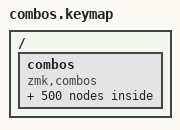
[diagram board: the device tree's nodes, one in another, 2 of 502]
/ {
    combos {
        compatible = "zmk,combos";
        #binding-cells = <2>;

        combo_the {
            key-positions = <12 11 17>;
            bindings      = < &kp T &kp H &kp E >;
        };

        combo_and {
            key-positions = <16 9 22>;
            bindings      = < &kp A &kp N &kp D >;
        };

        combo_in {
            key-positions = <18 9>;
            bindings      = < &kp I &kp N >;
        };

        combo_is {
            key-positions = <18 10>;
            bindings      = < &kp I &kp S >;
        };

        combo_it {
            key-positions = <18 12>;
            bindings      = < &kp I &kp T >;
        };

        combo_you {
            key-positions = <14 7 8>;
            bindings      = < &kp Y &kp O &kp U >;
        };

        combo_that {
            key-positions = <12 11 16>;
            bindings      = < &kp T &kp H &kp A >;
        };

        combo_he {
            key-positions = <11 17>;
            bindings      = < &kp H &kp E >;
        };

        combo_was {
            key-positions = <24 16 10>;
            bindings      = < &kp W &kp A &kp S >;
        };

        combo_for {
            key-positions = <1 7 25>;
            bindings      = < &kp F &kp O &kp R >;
        };

        combo_are {
            key-positions = <16 25 17>;
            bindings      = < &kp A &kp R &kp E >;
        };

        combo_with {
            key-positions = <24 18 12 11>;
            bindings      = < &kp W &kp I &kp T &kp H >;
        };

        combo_as {
            key-positions = <16 10>;
            bindings      = < &kp A &kp S >;
        };

        combo_his {
            key-positions = <11 18 10>;
            bindings      = < &kp H &kp I &kp S >;
        };

        combo_they {
            key-positions = <12 11 17 14>;
            bindings      = < &kp T &kp H &kp E &kp Y >;
        };

        combo_be {
            key-positions = <0 17>;
            bindings      = < &kp B &kp E >;
        };

        combo_at {
            key-positions = <16 12>;
            bindings      = < &kp A &kp T >;
        };

        combo_one {
            key-positions = <7 9 17>;
            bindings      = < &kp O &kp N &kp E >;
        };

        combo_have {
            key-positions = <11 16 20 17>;
            bindings      = < &kp H &kp A &kp V &kp E >;
        };

        combo_this {
            key-positions = <12 11 18 10>;
            bindings      = < &kp T &kp H &kp I &kp S >;
        };

        combo_from {
            key-positions = <1 25 7 13>;
            bindings      = < &kp F &kp R &kp O &kp M >;
        };

        combo_or {
            key-positions = <7 25>;
            bindings      = < &kp O &kp R >;
        };

        combo_had {
            key-positions = <11 16 22>;
            bindings      = < &kp H &kp A &kp D >;
        };

        combo_by {
            key-positions = <0 14>;
            bindings      = < &kp B &kp Y >;
        };

        combo_not {
            key-positions = <9 7 12>;
            bindings      = < &kp N &kp O &kp T >;
        };

        combo_word {
            key-positions = <24 7 25 22>;
            bindings      = < &kp W &kp O &kp R &kp D >;
        };

        combo_but {
            key-positions = <0 8 12>;
            bindings      = < &kp B &kp U &kp T >;
        };

        combo_what {
            key-positions = <24 11 16 12>;
            bindings      = < &kp W &kp H &kp A &kp T >;
        };

        combo_some {
            key-positions = <10 7 13 17>;
            bindings      = < &kp S &kp O &kp M &kp E >;
        };

        combo_we {
            key-positions = <24 17>;
            bindings      = < &kp W &kp E >;
        };

        combo_can {
            key-positions = <15 16 9>;
            bindings      = < &kp C &kp A &kp N >;
        };

        combo_out {
            key-positions = <7 8 12>;
            bindings      = < &kp O &kp U &kp T >;
        };

        combo_were {
            key-positions = <24 17 25>;
            bindings      = < &kp W &kp E &kp R >;
        };

        combo_all {
            key-positions = <16 2>;
            bindings      = < &kp A &kp L >;
        };

        combo_there {
            key-positions = <12 11 17 25>;
            bindings      = < &kp T &kp H &kp E &kp R >;
        };

        combo_when {
            key-positions = <24 11 17 9>;
            bindings      = < &kp W &kp H &kp E &kp N >;
        };

        combo_up {
            key-positions = <8 5>;
            bindings      = < &kp U &kp P >;
        };

        combo_use {
            key-positions = <8 10 17>;
            bindings      = < &kp U &kp S &kp E >;
        };

        combo_your {
            key-positions = <14 7 8 25>;
            bindings      = < &kp Y &kp O &kp U &kp R >;
        };

        combo_how {
            key-positions = <11 7 24>;
            bindings      = < &kp H &kp O &kp W >;
        };

        combo_said {
            key-positions = <10 16 18 22>;
            bindings      = < &kp S &kp A &kp I &kp D >;
        };

        combo_an {
            key-positions = <16 9>;
            bindings      = < &kp A &kp N >;
        };

        combo_each {
            key-positions = <17 16 15 11>;
            bindings      = < &kp E &kp A &kp C &kp H >;
        };

        combo_she {
            key-positions = <10 11 17>;
            bindings      = < &kp S &kp H &kp E >;
        };

        combo_which {
            key-positions = <24 11 18 15>;
            bindings      = < &kp W &kp H &kp I &kp C >;
        };

        combo_do {
            key-positions = <22 7>;
            bindings      = < &kp D &kp O >;
        };

        combo_their {
            key-positions = <12 11 18>;
            bindings      = < &kp T &kp H &kp I >;
        };

        combo_time {
            key-positions = <12 18 13 17>;
            bindings      = < &kp T &kp I &kp M &kp E >;
        };

        combo_if {
            key-positions = <18 1>;
            bindings      = < &kp I &kp F >;
        };

        combo_will {
            key-positions = <24 18 2>;
            bindings      = < &kp W &kp I &kp L >;
        };

        combo_way {
            key-positions = <24 16 14>;
            bindings      = < &kp W &kp A &kp Y >;
        };

        combo_about {
            key-positions = <16 0 7>;
            bindings      = < &kp A &kp B &kp O >;
        };

        combo_many {
            key-positions = <13 16 9 14>;
            bindings      = < &kp M &kp A &kp N &kp Y >;
        };

        combo_then {
            key-positions = <12 11 17 9>;
            bindings      = < &kp T &kp H &kp E &kp N >;
        };

        combo_them {
            key-positions = <12 11 17 13>;
            bindings      = < &kp T &kp H &kp E &kp M >;
        };

        combo_write {
            key-positions = <24 25 18>;
            bindings      = < &kp W &kp R &kp I >;
        };

        combo_would {
            key-positions = <24 7 8>;
            bindings      = < &kp W &kp O &kp U >;
        };

        combo_like {
            key-positions = <2 18 3 17>;
            bindings      = < &kp L &kp I &kp K &kp E >;
        };

        combo_so {
            key-positions = <10 7>;
            bindings      = < &kp S &kp O >;
        };

        combo_these {
            key-positions = <12 11 17 10>;
            bindings      = < &kp T &kp H &kp E &kp S >;
        };

        combo_her {
            key-positions = <11 17 25>;
            bindings      = < &kp H &kp E &kp R >;
        };

        combo_long {
            key-positions = <2 7 9 6>;
            bindings      = < &kp L &kp O &kp N &kp G >;
        };

        combo_make {
            key-positions = <13 16 3 17>;
            bindings      = < &kp M &kp A &kp K &kp E >;
        };

        combo_thing {
            key-positions = <12 11 9>;
            bindings      = < &kp T &kp H &kp N >;
        };

        combo_see {
            key-positions = <10 17>;
            bindings      = < &kp S &kp E >;
        };

        combo_him {
            key-positions = <11 18 13>;
            bindings      = < &kp H &kp I &kp M >;
        };

        combo_two {
            key-positions = <12 24 7>;
            bindings      = < &kp T &kp W &kp O >;
        };

        combo_has {
            key-positions = <11 16 10>;
            bindings      = < &kp H &kp A &kp S >;
        };

        combo_look {
            key-positions = <2 7 3>;
            bindings      = < &kp L &kp O &kp K >;
        };

        combo_more {
            key-positions = <13 7 25 17>;
            bindings      = < &kp M &kp O &kp R &kp E >;
        };

        combo_day {
            key-positions = <22 16 14>;
            bindings      = < &kp D &kp A &kp Y >;
        };

        combo_could {
            key-positions = <15 7 8>;
            bindings      = < &kp C &kp O &kp U >;
        };

        combo_go {
            key-positions = <6 7>;
            bindings      = < &kp G &kp O >;
        };

        combo_come {
            key-positions = <15 7 13 17>;
            bindings      = < &kp C &kp O &kp M &kp E >;
        };

        combo_did {
            key-positions = <22 18>;
            bindings      = < &kp D &kp I >;
        };

        combo_number {
            key-positions = <9 8 0>;
            bindings      = < &kp N &kp U &kp B >;
        };

        combo_sound {
            key-positions = <10 7 9>;
            bindings      = < &kp S &kp O &kp N >;
        };

        combo_most {
            key-positions = <13 7 10 12>;
            bindings      = < &kp M &kp O &kp S &kp T >;
        };

        combo_people {
            key-positions = <5 17 7 2>;
            bindings      = < &kp P &kp E &kp O &kp L >;
        };

        combo_my {
            key-positions = <13 14>;
            bindings      = < &kp M &kp Y >;
        };

        combo_over {
            key-positions = <7 20 17 25>;
            bindings      = < &kp O &kp V &kp E &kp R >;
        };

        combo_know {
            key-positions = <3 9 7 24>;
            bindings      = < &kp K &kp N &kp O &kp W >;
        };

        combo_water {
            key-positions = <24 16 17>;
            bindings      = < &kp W &kp A &kp E >;
        };

        combo_than {
            key-positions = <12 11 16 9>;
            bindings      = < &kp T &kp H &kp A &kp N >;
        };

        combo_call {
            key-positions = <15 16 2>;
            bindings      = < &kp C &kp A &kp L >;
        };

        combo_first {
            key-positions = <1 18 25>;
            bindings      = < &kp F &kp I &kp R >;
        };

        combo_may {
            key-positions = <13 16 14>;
            bindings      = < &kp M &kp A &kp Y >;
        };

        combo_down {
            key-positions = <22 7 24 9>;
            bindings      = < &kp D &kp O &kp W &kp N >;
        };

        combo_side {
            key-positions = <10 18 22 17>;
            bindings      = < &kp S &kp I &kp D &kp E >;
        };

        combo_been {
            key-positions = <0 17 9>;
            bindings      = < &kp B &kp E &kp N >;
        };

        combo_now {
            key-positions = <9 7 24>;
            bindings      = < &kp N &kp O &kp W >;
        };

        combo_find {
            key-positions = <1 18 9 22>;
            bindings      = < &kp F &kp I &kp N &kp D >;
        };

        combo_any {
            key-positions = <16 9 14>;
            bindings      = < &kp A &kp N &kp Y >;
        };

        combo_new {
            key-positions = <9 17 24>;
            bindings      = < &kp N &kp E &kp W >;
        };

        combo_work {
            key-positions = <24 7 25 3>;
            bindings      = < &kp W &kp O &kp R &kp K >;
        };

        combo_part {
            key-positions = <5 16 25 12>;
            bindings      = < &kp P &kp A &kp R &kp T >;
        };

        combo_take {
            key-positions = <12 16 3 17>;
            bindings      = < &kp T &kp A &kp K &kp E >;
        };

        combo_get {
            key-positions = <6 17 12>;
            bindings      = < &kp G &kp E &kp T >;
        };

        combo_place {
            key-positions = <5 2 16>;
            bindings      = < &kp P &kp L &kp A >;
        };

        combo_made {
            key-positions = <13 16 22 17>;
            bindings      = < &kp M &kp A &kp D &kp E >;
        };

        combo_live {
            key-positions = <2 18 20 17>;
            bindings      = < &kp L &kp I &kp V &kp E >;
        };

        combo_where {
            key-positions = <24 11 17 25>;
            bindings      = < &kp W &kp H &kp E &kp R >;
        };

        combo_after {
            key-positions = <16 1 17>;
            bindings      = < &kp A &kp F &kp E >;
        };

        combo_back {
            key-positions = <0 16 15 3>;
            bindings      = < &kp B &kp A &kp C &kp K >;
        };

        combo_little {
            key-positions = <2 18 12 17>;
            bindings      = < &kp L &kp I &kp T &kp E >;
        };

        combo_only {
            key-positions = <7 9 2 14>;
            bindings      = < &kp O &kp N &kp L &kp Y >;
        };

        combo_round {
            key-positions = <25 7 8>;
            bindings      = < &kp R &kp O &kp U >;
        };

        combo_man {
            key-positions = <13 16 9>;
            bindings      = < &kp M &kp A &kp N >;
        };

        combo_year {
            key-positions = <14 17 16 25>;
            bindings      = < &kp Y &kp E &kp A &kp R >;
        };

        combo_came {
            key-positions = <15 16 13 17>;
            bindings      = < &kp C &kp A &kp M &kp E >;
        };

        combo_show {
            key-positions = <10 11 7 24>;
            bindings      = < &kp S &kp H &kp O &kp W >;
        };

        combo_every {
            key-positions = <17 20 25 14>;
            bindings      = < &kp E &kp V &kp R &kp Y >;
        };

        combo_good {
            key-positions = <6 7 22>;
            bindings      = < &kp G &kp O &kp D >;
        };

        combo_me {
            key-positions = <13 17>;
            bindings      = < &kp M &kp E >;
        };

        combo_give {
            key-positions = <6 18 20 17>;
            bindings      = < &kp G &kp I &kp V &kp E >;
        };

        combo_under {
            key-positions = <8 9 22>;
            bindings      = < &kp U &kp N &kp D >;
        };

        combo_name {
            key-positions = <9 16 13 17>;
            bindings      = < &kp N &kp A &kp M &kp E >;
        };

        combo_through {
            key-positions = <12 11 25>;
            bindings      = < &kp T &kp H &kp R >;
        };

        combo_just {
            key-positions = <21 8 10 12>;
            bindings      = < &kp J &kp U &kp S &kp T >;
        };

        combo_sentence {
            key-positions = <10 17 9>;
            bindings      = < &kp S &kp E &kp N >;
        };

        combo_great {
            key-positions = <6 25 17>;
            bindings      = < &kp G &kp R &kp E >;
        };

        combo_think {
            key-positions = <12 11 3>;
            bindings      = < &kp T &kp H &kp K >;
        };

        combo_say {
            key-positions = <10 16 14>;
            bindings      = < &kp S &kp A &kp Y >;
        };

        combo_help {
            key-positions = <11 17 2 5>;
            bindings      = < &kp H &kp E &kp L &kp P >;
        };

        combo_low {
            key-positions = <2 7 24>;
            bindings      = < &kp L &kp O &kp W >;
        };

        combo_line {
            key-positions = <2 18 9 17>;
            bindings      = < &kp L &kp I &kp N &kp E >;
        };

        combo_differ {
            key-positions = <22 1 25>;
            bindings      = < &kp D &kp F &kp R >;
        };

        combo_turn {
            key-positions = <12 8 25 9>;
            bindings      = < &kp T &kp U &kp R &kp N >;
        };

        combo_cause {
            key-positions = <15 16 8>;
            bindings      = < &kp C &kp A &kp U >;
        };

        combo_much {
            key-positions = <13 8 15 11>;
            bindings      = < &kp M &kp U &kp C &kp H >;
        };

        combo_before {
            key-positions = <0 17 1>;
            bindings      = < &kp B &kp E &kp F >;
        };

        combo_move {
            key-positions = <13 7 20 17>;
            bindings      = < &kp M &kp O &kp V &kp E >;
        };

        combo_right {
            key-positions = <25 18 6>;
            bindings      = < &kp R &kp I &kp G >;
        };

        combo_boy {
            key-positions = <0 7 14>;
            bindings      = < &kp B &kp O &kp Y >;
        };

        combo_old {
            key-positions = <7 2 22>;
            bindings      = < &kp O &kp L &kp D >;
        };

        combo_too {
            key-positions = <12 7>;
            bindings      = < &kp T &kp O >;
        };

        combo_same {
            key-positions = <10 16 13 17>;
            bindings      = < &kp S &kp A &kp M &kp E >;
        };

        combo_tell {
            key-positions = <12 17 2>;
            bindings      = < &kp T &kp E &kp L >;
        };

        combo_does {
            key-positions = <22 7 17 10>;
            bindings      = < &kp D &kp O &kp E &kp S >;
        };

        combo_want {
            key-positions = <24 16 9 12>;
            bindings      = < &kp W &kp A &kp N &kp T >;
        };

        combo_air {
            key-positions = <16 18 25>;
            bindings      = < &kp A &kp I &kp R >;
        };

        combo_well {
            key-positions = <24 17 2>;
            bindings      = < &kp W &kp E &kp L >;
        };

        combo_also {
            key-positions = <16 2 10 7>;
            bindings      = < &kp A &kp L &kp S &kp O >;
        };

        combo_play {
            key-positions = <5 2 16 14>;
            bindings      = < &kp P &kp L &kp A &kp Y >;
        };

        combo_small {
            key-positions = <10 13 16 2>;
            bindings      = < &kp S &kp M &kp A &kp L >;
        };

        combo_end {
            key-positions = <17 9 22>;
            bindings      = < &kp E &kp N &kp D >;
        };

        combo_put {
            key-positions = <5 8 12>;
            bindings      = < &kp P &kp U &kp T >;
        };

        combo_home {
            key-positions = <11 7 13 17>;
            bindings      = < &kp H &kp O &kp M &kp E >;
        };

        combo_read {
            key-positions = <25 17 16 22>;
            bindings      = < &kp R &kp E &kp A &kp D >;
        };

        combo_hand {
            key-positions = <11 16 9 22>;
            bindings      = < &kp H &kp A &kp N &kp D >;
        };

        combo_port {
            key-positions = <5 7 25 12>;
            bindings      = < &kp P &kp O &kp R &kp T >;
        };

        combo_large {
            key-positions = <2 16 25>;
            bindings      = < &kp L &kp A &kp R >;
        };

        combo_spell {
            key-positions = <10 5 17 2>;
            bindings      = < &kp S &kp P &kp E &kp L >;
        };

        combo_add {
            key-positions = <16 22>;
            bindings      = < &kp A &kp D >;
        };

        combo_even {
            key-positions = <17 20 9>;
            bindings      = < &kp E &kp V &kp N >;
        };

        combo_land {
            key-positions = <2 16 9 22>;
            bindings      = < &kp L &kp A &kp N &kp D >;
        };

        combo_must {
            key-positions = <13 8 10 12>;
            bindings      = < &kp M &kp U &kp S &kp T >;
        };

        combo_big {
            key-positions = <0 18 6>;
            bindings      = < &kp B &kp I &kp G >;
        };

        combo_high {
            key-positions = <11 18 6>;
            bindings      = < &kp H &kp I &kp G >;
        };

        combo_such {
            key-positions = <10 8 15 11>;
            bindings      = < &kp S &kp U &kp C &kp H >;
        };

        combo_follow {
            key-positions = <1 7 2 24>;
            bindings      = < &kp F &kp O &kp L &kp W >;
        };

        combo_act {
            key-positions = <16 15 12>;
            bindings      = < &kp A &kp C &kp T >;
        };

        combo_why {
            key-positions = <24 11 14>;
            bindings      = < &kp W &kp H &kp Y >;
        };

        combo_ask {
            key-positions = <16 10 3>;
            bindings      = < &kp A &kp S &kp K >;
        };

        combo_men {
            key-positions = <13 17 9>;
            bindings      = < &kp M &kp E &kp N >;
        };

        combo_change {
            key-positions = <15 11 16>;
            bindings      = < &kp C &kp H &kp A >;
        };

        combo_went {
            key-positions = <24 17 9 12>;
            bindings      = < &kp W &kp E &kp N &kp T >;
        };

        combo_light {
            key-positions = <2 18 6>;
            bindings      = < &kp L &kp I &kp G >;
        };

        combo_off {
            key-positions = <7 1>;
            bindings      = < &kp O &kp F >;
        };

        combo_house {
            key-positions = <11 7 8>;
            bindings      = < &kp H &kp O &kp U >;
        };

        combo_picture {
            key-positions = <5 18 15>;
            bindings      = < &kp P &kp I &kp C >;
        };

        combo_try {
            key-positions = <12 25 14>;
            bindings      = < &kp T &kp R &kp Y >;
        };

        combo_us {
            key-positions = <8 10>;
            bindings      = < &kp U &kp S >;
        };

        combo_again {
            key-positions = <16 6 18 9>;
            bindings      = < &kp A &kp G &kp I &kp N >;
        };

        combo_animal {
            key-positions = <16 9 18>;
            bindings      = < &kp A &kp N &kp I >;
        };

        combo_point {
            key-positions = <5 7 18>;
            bindings      = < &kp P &kp O &kp I >;
        };

        combo_mother {
            key-positions = <13 12 11>;
            bindings      = < &kp M &kp T &kp H >;
        };

        combo_world {
            key-positions = <24 7 25>;
            bindings      = < &kp W &kp O &kp R >;
        };

        combo_near {
            key-positions = <9 17 16 25>;
            bindings      = < &kp N &kp E &kp A &kp R >;
        };

        combo_build {
            key-positions = <0 8 18>;
            bindings      = < &kp B &kp U &kp I >;
        };

        combo_self {
            key-positions = <10 17 2 1>;
            bindings      = < &kp S &kp E &kp L &kp F >;
        };

        combo_earth {
            key-positions = <17 16 12>;
            bindings      = < &kp E &kp A &kp T >;
        };

        combo_head {
            key-positions = <11 17 16 22>;
            bindings      = < &kp H &kp E &kp A &kp D >;
        };

        combo_stand {
            key-positions = <10 12 16>;
            bindings      = < &kp S &kp T &kp A >;
        };

        combo_page {
            key-positions = <5 16 6 17>;
            bindings      = < &kp P &kp A &kp G &kp E >;
        };

        combo_should {
            key-positions = <10 11 7>;
            bindings      = < &kp S &kp H &kp O >;
        };

        combo_country {
            key-positions = <15 7 9>;
            bindings      = < &kp C &kp O &kp N >;
        };

        combo_found {
            key-positions = <1 7 8>;
            bindings      = < &kp F &kp O &kp U >;
        };

        combo_answer {
            key-positions = <16 9 10>;
            bindings      = < &kp A &kp N &kp S >;
        };

        combo_school {
            key-positions = <10 15 11>;
            bindings      = < &kp S &kp C &kp H >;
        };

        combo_study {
            key-positions = <10 12 8>;
            bindings      = < &kp S &kp T &kp U >;
        };

        combo_still {
            key-positions = <10 12 18 2>;
            bindings      = < &kp S &kp T &kp I &kp L >;
        };

        combo_learn {
            key-positions = <2 17 16>;
            bindings      = < &kp L &kp E &kp A >;
        };

        combo_plant {
            key-positions = <5 2 9>;
            bindings      = < &kp P &kp L &kp N >;
        };

        combo_cover {
            key-positions = <15 7 20>;
            bindings      = < &kp C &kp O &kp V >;
        };

        combo_food {
            key-positions = <1 7 22>;
            bindings      = < &kp F &kp O &kp D >;
        };

        combo_sun {
            key-positions = <10 8 9>;
            bindings      = < &kp S &kp U &kp N >;
        };

        combo_four {
            key-positions = <1 7 8 25>;
            bindings      = < &kp F &kp O &kp U &kp R >;
        };

        combo_between {
            key-positions = <0 17 12>;
            bindings      = < &kp B &kp E &kp T >;
        };

        combo_state {
            key-positions = <10 12 16 17>;
            bindings      = < &kp S &kp T &kp A &kp E >;
        };

        combo_keep {
            key-positions = <3 17 5>;
            bindings      = < &kp K &kp E &kp P >;
        };

        combo_eye {
            key-positions = <17 14>;
            bindings      = < &kp E &kp Y >;
        };

        combo_never {
            key-positions = <9 17 20 25>;
            bindings      = < &kp N &kp E &kp V &kp R >;
        };

        combo_last {
            key-positions = <2 16 10 12>;
            bindings      = < &kp L &kp A &kp S &kp T >;
        };

        combo_thought {
            key-positions = <12 11 7>;
            bindings      = < &kp T &kp H &kp O >;
        };

        combo_city {
            key-positions = <15 18 12 14>;
            bindings      = < &kp C &kp I &kp T &kp Y >;
        };

        combo_tree {
            key-positions = <12 25 17>;
            bindings      = < &kp T &kp R &kp E >;
        };

        combo_cross {
            key-positions = <15 25 7 10>;
            bindings      = < &kp C &kp R &kp O &kp S >;
        };

        combo_farm {
            key-positions = <1 16 25 13>;
            bindings      = < &kp F &kp A &kp R &kp M >;
        };

        combo_hard {
            key-positions = <11 16 25 22>;
            bindings      = < &kp H &kp A &kp R &kp D >;
        };

        combo_start {
            key-positions = <10 12 16 25>;
            bindings      = < &kp S &kp T &kp A &kp R >;
        };

        combo_might {
            key-positions = <13 18 6>;
            bindings      = < &kp M &kp I &kp G >;
        };

        combo_story {
            key-positions = <10 12 7>;
            bindings      = < &kp S &kp T &kp O >;
        };

        combo_far {
            key-positions = <1 16 25>;
            bindings      = < &kp F &kp A &kp R >;
        };

        combo_sea {
            key-positions = <10 17 16>;
            bindings      = < &kp S &kp E &kp A >;
        };

        combo_draw {
            key-positions = <22 25 16 24>;
            bindings      = < &kp D &kp R &kp A &kp W >;
        };

        combo_left {
            key-positions = <2 17 1 12>;
            bindings      = < &kp L &kp E &kp F &kp T >;
        };

        combo_late {
            key-positions = <2 16 12 17>;
            bindings      = < &kp L &kp A &kp T &kp E >;
        };

        combo_run {
            key-positions = <25 8 9>;
            bindings      = < &kp R &kp U &kp N >;
        };

        combo_while {
            key-positions = <24 11 18>;
            bindings      = < &kp W &kp H &kp I >;
        };

        combo_press {
            key-positions = <5 25 17 10>;
            bindings      = < &kp P &kp R &kp E &kp S >;
        };

        combo_close {
            key-positions = <15 2 7>;
            bindings      = < &kp C &kp L &kp O >;
        };

        combo_night {
            key-positions = <9 18 11>;
            bindings      = < &kp N &kp I &kp H >;
        };

        combo_real {
            key-positions = <25 17 16 2>;
            bindings      = < &kp R &kp E &kp A &kp L >;
        };

        combo_life {
            key-positions = <2 18 1 17>;
            bindings      = < &kp L &kp I &kp F &kp E >;
        };

        combo_few {
            key-positions = <1 17 24>;
            bindings      = < &kp F &kp E &kp W >;
        };

        combo_north {
            key-positions = <9 7 25>;
            bindings      = < &kp N &kp O &kp R >;
        };

        combo_open {
            key-positions = <7 5 17 9>;
            bindings      = < &kp O &kp P &kp E &kp N >;
        };

        combo_seem {
            key-positions = <10 17 13>;
            bindings      = < &kp S &kp E &kp M >;
        };

        combo_together {
            key-positions = <12 6 11>;
            bindings      = < &kp T &kp G &kp H >;
        };

        combo_next {
            key-positions = <9 17 19 12>;
            bindings      = < &kp N &kp E &kp X &kp T >;
        };

        combo_white {
            key-positions = <24 11 12>;
            bindings      = < &kp W &kp H &kp T >;
        };

        combo_children {
            key-positions = <15 11 18>;
            bindings      = < &kp C &kp H &kp I >;
        };

        combo_begin {
            key-positions = <0 17 6>;
            bindings      = < &kp B &kp E &kp G >;
        };

        combo_got {
            key-positions = <6 7 12>;
            bindings      = < &kp G &kp O &kp T >;
        };

        combo_walk {
            key-positions = <24 16 2 3>;
            bindings      = < &kp W &kp A &kp L &kp K >;
        };

        combo_example {
            key-positions = <17 19 16>;
            bindings      = < &kp E &kp X &kp A >;
        };

        combo_group {
            key-positions = <6 25 7>;
            bindings      = < &kp G &kp R &kp O >;
        };

        combo_always {
            key-positions = <16 2 24>;
            bindings      = < &kp A &kp L &kp W >;
        };

        combo_music {
            key-positions = <13 8 10>;
            bindings      = < &kp M &kp U &kp S >;
        };

        combo_those {
            key-positions = <12 11 10>;
            bindings      = < &kp T &kp H &kp S >;
        };

        combo_both {
            key-positions = <0 7 12 11>;
            bindings      = < &kp B &kp O &kp T &kp H >;
        };

        combo_mark {
            key-positions = <13 16 25 3>;
            bindings      = < &kp M &kp A &kp R &kp K >;
        };

        combo_often {
            key-positions = <7 1 12>;
            bindings      = < &kp O &kp F &kp T >;
        };

        combo_letter {
            key-positions = <2 17 12 25>;
            bindings      = < &kp L &kp E &kp T &kp R >;
        };

        combo_until {
            key-positions = <8 9 12>;
            bindings      = < &kp U &kp N &kp T >;
        };

        combo_mile {
            key-positions = <13 18 2 17>;
            bindings      = < &kp M &kp I &kp L &kp E >;
        };

        combo_river {
            key-positions = <25 18 20 17>;
            bindings      = < &kp R &kp I &kp V &kp E >;
        };

        combo_car {
            key-positions = <15 16 25>;
            bindings      = < &kp C &kp A &kp R >;
        };

        combo_feet {
            key-positions = <1 17 12>;
            bindings      = < &kp F &kp E &kp T >;
        };

        combo_care {
            key-positions = <15 16 25 17>;
            bindings      = < &kp C &kp A &kp R &kp E >;
        };

        combo_second {
            key-positions = <10 17 15>;
            bindings      = < &kp S &kp E &kp C >;
        };

        combo_book {
            key-positions = <0 7 3>;
            bindings      = < &kp B &kp O &kp K >;
        };

        combo_carry {
            key-positions = <15 16 25 14>;
            bindings      = < &kp C &kp A &kp R &kp Y >;
        };

        combo_took {
            key-positions = <12 7 3>;
            bindings      = < &kp T &kp O &kp K >;
        };

        combo_science {
            key-positions = <10 15 18>;
            bindings      = < &kp S &kp C &kp I >;
        };

        combo_room {
            key-positions = <25 7 13>;
            bindings      = < &kp R &kp O &kp M >;
        };

        combo_friend {
            key-positions = <1 25 17>;
            bindings      = < &kp F &kp R &kp E >;
        };

        combo_began {
            key-positions = <0 17 16>;
            bindings      = < &kp B &kp E &kp A >;
        };

        combo_idea {
            key-positions = <18 22 17 16>;
            bindings      = < &kp I &kp D &kp E &kp A >;
        };

        combo_fish {
            key-positions = <1 18 10 11>;
            bindings      = < &kp F &kp I &kp S &kp H >;
        };

        combo_mountain {
            key-positions = <13 7 8>;
            bindings      = < &kp M &kp O &kp U >;
        };

        combo_stop {
            key-positions = <10 12 7 5>;
            bindings      = < &kp S &kp T &kp O &kp P >;
        };

        combo_once {
            key-positions = <7 9 15 17>;
            bindings      = < &kp O &kp N &kp C &kp E >;
        };

        combo_base {
            key-positions = <0 16 10 17>;
            bindings      = < &kp B &kp A &kp S &kp E >;
        };

        combo_hear {
            key-positions = <11 17 16 25>;
            bindings      = < &kp H &kp E &kp A &kp R >;
        };

        combo_horse {
            key-positions = <11 7 25>;
            bindings      = < &kp H &kp O &kp R >;
        };

        combo_cut {
            key-positions = <15 8 12>;
            bindings      = < &kp C &kp U &kp T >;
        };

        combo_sure {
            key-positions = <10 8 25 17>;
            bindings      = < &kp S &kp U &kp R &kp E >;
        };

        combo_watch {
            key-positions = <24 16 12>;
            bindings      = < &kp W &kp A &kp T >;
        };

        combo_color {
            key-positions = <15 7 2 25>;
            bindings      = < &kp C &kp O &kp L &kp R >;
        };

        combo_face {
            key-positions = <1 16 15 17>;
            bindings      = < &kp F &kp A &kp C &kp E >;
        };

        combo_wood {
            key-positions = <24 7 22>;
            bindings      = < &kp W &kp O &kp D >;
        };

        combo_main {
            key-positions = <13 16 18 9>;
            bindings      = < &kp M &kp A &kp I &kp N >;
        };

        combo_enough {
            key-positions = <17 9 8>;
            bindings      = < &kp E &kp N &kp U >;
        };

        combo_plain {
            key-positions = <5 2 18>;
            bindings      = < &kp P &kp L &kp I >;
        };

        combo_girl {
            key-positions = <6 18 25 2>;
            bindings      = < &kp G &kp I &kp R &kp L >;
        };

        combo_usual {
            key-positions = <8 10 16 2>;
            bindings      = < &kp U &kp S &kp A &kp L >;
        };

        combo_young {
            key-positions = <14 7 9>;
            bindings      = < &kp Y &kp O &kp N >;
        };

        combo_ready {
            key-positions = <25 17 14>;
            bindings      = < &kp R &kp E &kp Y >;
        };

        combo_above {
            key-positions = <16 0 20>;
            bindings      = < &kp A &kp B &kp V >;
        };

        combo_ever {
            key-positions = <17 20 25>;
            bindings      = < &kp E &kp V &kp R >;
        };

        combo_red {
            key-positions = <25 17 22>;
            bindings      = < &kp R &kp E &kp D >;
        };

        combo_though {
            key-positions = <12 11 8>;
            bindings      = < &kp T &kp H &kp U >;
        };

        combo_feel {
            key-positions = <1 17 2>;
            bindings      = < &kp F &kp E &kp L >;
        };

        combo_talk {
            key-positions = <12 16 2 3>;
            bindings      = < &kp T &kp A &kp L &kp K >;
        };

        combo_bird {
            key-positions = <0 18 25 22>;
            bindings      = < &kp B &kp I &kp R &kp D >;
        };

        combo_body {
            key-positions = <0 7 22 14>;
            bindings      = < &kp B &kp O &kp D &kp Y >;
        };

        combo_family {
            key-positions = <1 16 13>;
            bindings      = < &kp F &kp A &kp M >;
        };

        combo_direct {
            key-positions = <22 18 25>;
            bindings      = < &kp D &kp I &kp R >;
        };

        combo_pose {
            key-positions = <5 7 10 17>;
            bindings      = < &kp P &kp O &kp S &kp E >;
        };

        combo_leave {
            key-positions = <2 17 16 20>;
            bindings      = < &kp L &kp E &kp A &kp V >;
        };

        combo_song {
            key-positions = <10 7 9 6>;
            bindings      = < &kp S &kp O &kp N &kp G >;
        };

        combo_measure {
            key-positions = <13 17 16>;
            bindings      = < &kp M &kp E &kp A >;
        };

        combo_door {
            key-positions = <22 7 25>;
            bindings      = < &kp D &kp O &kp R >;
        };

        combo_product {
            key-positions = <5 25 7>;
            bindings      = < &kp P &kp R &kp O >;
        };

        combo_black {
            key-positions = <0 2 16>;
            bindings      = < &kp B &kp L &kp A >;
        };

        combo_short {
            key-positions = <10 11 25>;
            bindings      = < &kp S &kp H &kp R >;
        };

        combo_numeral {
            key-positions = <9 8 13>;
            bindings      = < &kp N &kp U &kp M >;
        };

        combo_class {
            key-positions = <15 2 16 10>;
            bindings      = < &kp C &kp L &kp A &kp S >;
        };

        combo_wind {
            key-positions = <24 18 9 22>;
            bindings      = < &kp W &kp I &kp N &kp D >;
        };

        combo_question {
            key-positions = <4 8 9>;
            bindings      = < &kp Q &kp U &kp N >;
        };

        combo_happen {
            key-positions = <11 16 5>;
            bindings      = < &kp H &kp A &kp P >;
        };

        combo_complete {
            key-positions = <15 7 13>;
            bindings      = < &kp C &kp O &kp M >;
        };

        combo_ship {
            key-positions = <10 11 18 5>;
            bindings      = < &kp S &kp H &kp I &kp P >;
        };

        combo_half {
            key-positions = <11 16 2 1>;
            bindings      = < &kp H &kp A &kp L &kp F >;
        };

        combo_rock {
            key-positions = <25 7 15 3>;
            bindings      = < &kp R &kp O &kp C &kp K >;
        };

        combo_order {
            key-positions = <7 25 22 17>;
            bindings      = < &kp O &kp R &kp D &kp E >;
        };

        combo_fire {
            key-positions = <1 18 25 17>;
            bindings      = < &kp F &kp I &kp R &kp E >;
        };

        combo_south {
            key-positions = <10 8 11>;
            bindings      = < &kp S &kp U &kp H >;
        };

        combo_problem {
            key-positions = <5 25 0>;
            bindings      = < &kp P &kp R &kp B >;
        };

        combo_piece {
            key-positions = <5 18 17 15>;
            bindings      = < &kp P &kp I &kp E &kp C >;
        };

        combo_told {
            key-positions = <12 7 2 22>;
            bindings      = < &kp T &kp O &kp L &kp D >;
        };

        combo_knew {
            key-positions = <3 9 17 24>;
            bindings      = < &kp K &kp N &kp E &kp W >;
        };

        combo_pass {
            key-positions = <5 16 10>;
            bindings      = < &kp P &kp A &kp S >;
        };

        combo_since {
            key-positions = <10 18 9>;
            bindings      = < &kp S &kp I &kp N >;
        };

        combo_top {
            key-positions = <12 7 5>;
            bindings      = < &kp T &kp O &kp P >;
        };

        combo_whole {
            key-positions = <24 11 2>;
            bindings      = < &kp W &kp H &kp L >;
        };

        combo_king {
            key-positions = <3 18 9 6>;
            bindings      = < &kp K &kp I &kp N &kp G >;
        };

        combo_space {
            key-positions = <10 5 15>;
            bindings      = < &kp S &kp P &kp C >;
        };

        combo_heard {
            key-positions = <11 17 16>;
            bindings      = < &kp H &kp E &kp A >;
        };

        combo_best {
            key-positions = <0 17 10 12>;
            bindings      = < &kp B &kp E &kp S &kp T >;
        };

        combo_hour {
            key-positions = <11 7 8 25>;
            bindings      = < &kp H &kp O &kp U &kp R >;
        };

        combo_better {
            key-positions = <0 17 12 25>;
            bindings      = < &kp B &kp E &kp T &kp R >;
        };

        combo_true {
            key-positions = <12 25 8 17>;
            bindings      = < &kp T &kp R &kp U &kp E >;
        };

        combo_during {
            key-positions = <22 8 25>;
            bindings      = < &kp D &kp U &kp R >;
        };

        combo_hundred {
            key-positions = <11 8 9>;
            bindings      = < &kp H &kp U &kp N >;
        };

        combo_remember {
            key-positions = <25 17 13 0>;
            bindings      = < &kp R &kp E &kp M &kp B >;
        };

        combo_step {
            key-positions = <10 12 17 5>;
            bindings      = < &kp S &kp T &kp E &kp P >;
        };

        combo_early {
            key-positions = <17 16 14>;
            bindings      = < &kp E &kp A &kp Y >;
        };

        combo_hold {
            key-positions = <11 7 2 22>;
            bindings      = < &kp H &kp O &kp L &kp D >;
        };

        combo_west {
            key-positions = <24 17 10 12>;
            bindings      = < &kp W &kp E &kp S &kp T >;
        };

        combo_ground {
            key-positions = <6 25 8>;
            bindings      = < &kp G &kp R &kp U >;
        };

        combo_interest {
            key-positions = <18 9 25>;
            bindings      = < &kp I &kp N &kp R >;
        };

        combo_fast {
            key-positions = <1 16 10 12>;
            bindings      = < &kp F &kp A &kp S &kp T >;
        };

        combo_verb {
            key-positions = <20 17 25 0>;
            bindings      = < &kp V &kp E &kp R &kp B >;
        };

        combo_sing {
            key-positions = <10 18 9 6>;
            bindings      = < &kp S &kp I &kp N &kp G >;
        };

        combo_listen {
            key-positions = <2 18 10>;
            bindings      = < &kp L &kp I &kp S >;
        };

        combo_six {
            key-positions = <10 18 19>;
            bindings      = < &kp S &kp I &kp X >;
        };

        combo_table {
            key-positions = <12 16 0>;
            bindings      = < &kp T &kp A &kp B >;
        };

        combo_travel {
            key-positions = <12 25 16>;
            bindings      = < &kp T &kp R &kp A >;
        };

        combo_less {
            key-positions = <2 17 10 10>;
            bindings      = < &kp L &kp E &kp S &kp S >;
        };

        combo_morning {
            key-positions = <13 7 18>;
            bindings      = < &kp M &kp O &kp I >;
        };

        combo_ten {
            key-positions = <12 17 9>;
            bindings      = < &kp T &kp E &kp N >;
        };

        combo_simple {
            key-positions = <10 18 13>;
            bindings      = < &kp S &kp I &kp M >;
        };

        combo_several {
            key-positions = <10 17 20>;
            bindings      = < &kp S &kp E &kp V >;
        };

        combo_vowel {
            key-positions = <20 7 24>;
            bindings      = < &kp V &kp O &kp W >;
        };

        combo_toward {
            key-positions = <12 7 16>;
            bindings      = < &kp T &kp O &kp A >;
        };

        combo_war {
            key-positions = <24 16 25>;
            bindings      = < &kp W &kp A &kp R >;
        };

        combo_lay {
            key-positions = <2 16 14>;
            bindings      = < &kp L &kp A &kp Y >;
        };

        combo_against {
            key-positions = <16 6 18>;
            bindings      = < &kp A &kp G &kp I >;
        };

        combo_pattern {
            key-positions = <5 16 12>;
            bindings      = < &kp P &kp A &kp T >;
        };

        combo_slow {
            key-positions = <10 2 7 24>;
            bindings      = < &kp S &kp L &kp O &kp W >;
        };

        combo_love {
            key-positions = <2 7 20 17>;
            bindings      = < &kp L &kp O &kp V &kp E >;
        };

        combo_person {
            key-positions = <5 17 10>;
            bindings      = < &kp P &kp E &kp S >;
        };

        combo_money {
            key-positions = <13 7 9>;
            bindings      = < &kp M &kp O &kp N >;
        };

        combo_serve {
            key-positions = <10 17 25 20>;
            bindings      = < &kp S &kp E &kp R &kp V >;
        };

        combo_appear {
            key-positions = <16 5 17 25>;
            bindings      = < &kp A &kp P &kp E &kp R >;
        };

        combo_road {
            key-positions = <25 7 16 22>;
            bindings      = < &kp R &kp O &kp A &kp D >;
        };

        combo_map {
            key-positions = <13 16 5>;
            bindings      = < &kp M &kp A &kp P >;
        };

        combo_rain {
            key-positions = <25 16 18 9>;
            bindings      = < &kp R &kp A &kp I &kp N >;
        };

        combo_rule {
            key-positions = <25 8 2 17>;
            bindings      = < &kp R &kp U &kp L &kp E >;
        };

        combo_govern {
            key-positions = <6 7 20>;
            bindings      = < &kp G &kp O &kp V >;
        };

        combo_pull {
            key-positions = <5 8 2>;
            bindings      = < &kp P &kp U &kp L >;
        };

        combo_cold {
            key-positions = <15 7 2 22>;
            bindings      = < &kp C &kp O &kp L &kp D >;
        };

        combo_notice {
            key-positions = <9 12 18>;
            bindings      = < &kp N &kp T &kp I >;
        };

        combo_voice {
            key-positions = <20 7 18>;
            bindings      = < &kp V &kp O &kp I >;
        };

        combo_unit {
            key-positions = <8 9 18 12>;
            bindings      = < &kp U &kp N &kp I &kp T >;
        };

        combo_power {
            key-positions = <5 7 24>;
            bindings      = < &kp P &kp O &kp W >;
        };

        combo_town {
            key-positions = <12 7 24 9>;
            bindings      = < &kp T &kp O &kp W &kp N >;
        };

        combo_fine {
            key-positions = <1 18 9 17>;
            bindings      = < &kp F &kp I &kp N &kp E >;
        };

        combo_certain {
            key-positions = <15 17 25>;
            bindings      = < &kp C &kp E &kp R >;
        };

        combo_fly {
            key-positions = <1 2 14>;
            bindings      = < &kp F &kp L &kp Y >;
        };

        combo_fall {
            key-positions = <1 16 2>;
            bindings      = < &kp F &kp A &kp L >;
        };

        combo_lead {
            key-positions = <2 17 16 22>;
            bindings      = < &kp L &kp E &kp A &kp D >;
        };

        combo_cry {
            key-positions = <15 25 14>;
            bindings      = < &kp C &kp R &kp Y >;
        };

        combo_machine {
            key-positions = <13 16 15>;
            bindings      = < &kp M &kp A &kp C >;
        };

        combo_note {
            key-positions = <9 7 12 17>;
            bindings      = < &kp N &kp O &kp T &kp E >;
        };

        combo_wait {
            key-positions = <24 16 18 12>;
            bindings      = < &kp W &kp A &kp I &kp T >;
        };

        combo_plan {
            key-positions = <5 2 16 9>;
            bindings      = < &kp P &kp L &kp A &kp N >;
        };

        combo_figure {
            key-positions = <1 18 6>;
            bindings      = < &kp F &kp I &kp G >;
        };

        combo_noun {
            key-positions = <9 7 8>;
            bindings      = < &kp N &kp O &kp U >;
        };

        combo_field {
            key-positions = <1 18 17>;
            bindings      = < &kp F &kp I &kp E >;
        };

        combo_rest {
            key-positions = <25 17 10 12>;
            bindings      = < &kp R &kp E &kp S &kp T >;
        };

        combo_correct {
            key-positions = <15 7 25>;
            bindings      = < &kp C &kp O &kp R >;
        };

        combo_able {
            key-positions = <16 0 2 17>;
            bindings      = < &kp A &kp B &kp L &kp E >;
        };

        combo_pound {
            key-positions = <5 7 8>;
            bindings      = < &kp P &kp O &kp U >;
        };

        combo_done {
            key-positions = <22 7 9 17>;
            bindings      = < &kp D &kp O &kp N &kp E >;
        };

        combo_beauty {
            key-positions = <0 17 8>;
            bindings      = < &kp B &kp E &kp U >;
        };

        combo_drive {
            key-positions = <22 25 20>;
            bindings      = < &kp D &kp R &kp V >;
        };

        combo_stood {
            key-positions = <10 12 7 22>;
            bindings      = < &kp S &kp T &kp O &kp D >;
        };

        combo_contain {
            key-positions = <15 7 12>;
            bindings      = < &kp C &kp O &kp T >;
        };

        combo_front {
            key-positions = <1 25 9>;
            bindings      = < &kp F &kp R &kp N >;
        };

        combo_teach {
            key-positions = <12 17 15>;
            bindings      = < &kp T &kp E &kp C >;
        };

        combo_week {
            key-positions = <24 17 3>;
            bindings      = < &kp W &kp E &kp K >;
        };

        combo_final {
            key-positions = <1 18 9>;
            bindings      = < &kp F &kp I &kp N >;
        };

        combo_gave {
            key-positions = <6 16 20 17>;
            bindings      = < &kp G &kp A &kp V &kp E >;
        };

        combo_green {
            key-positions = <6 25 17 9>;
            bindings      = < &kp G &kp R &kp E &kp N >;
        };

        combo_oh {
            key-positions = <7 11>;
            bindings      = < &kp O &kp H >;
        };

        combo_quick {
            key-positions = <4 8 18>;
            bindings      = < &kp Q &kp U &kp I >;
        };

        combo_develop {
            key-positions = <22 17 20>;
            bindings      = < &kp D &kp E &kp V >;
        };

        combo_ocean {
            key-positions = <7 15 17>;
            bindings      = < &kp O &kp C &kp E >;
        };

        combo_warm {
            key-positions = <24 16 25 13>;
            bindings      = < &kp W &kp A &kp R &kp M >;
        };

        combo_minute {
            key-positions = <13 18 9>;
            bindings      = < &kp M &kp I &kp N >;
        };

        combo_strong {
            key-positions = <10 12 25>;
            bindings      = < &kp S &kp T &kp R >;
        };

        combo_special {
            key-positions = <10 5 18>;
            bindings      = < &kp S &kp P &kp I >;
        };

        combo_mind {
            key-positions = <13 18 9 22>;
            bindings      = < &kp M &kp I &kp N &kp D >;
        };

        combo_behind {
            key-positions = <0 17 11>;
            bindings      = < &kp B &kp E &kp H >;
        };

        combo_clear {
            key-positions = <15 2 17>;
            bindings      = < &kp C &kp L &kp E >;
        };

        combo_tail {
            key-positions = <12 16 18 2>;
            bindings      = < &kp T &kp A &kp I &kp L >;
        };

        combo_produce {
            key-positions = <5 25 22>;
            bindings      = < &kp P &kp R &kp D >;
        };

        combo_fact {
            key-positions = <1 16 15 12>;
            bindings      = < &kp F &kp A &kp C &kp T >;
        };

        combo_inch {
            key-positions = <18 9 15 11>;
            bindings      = < &kp I &kp N &kp C &kp H >;
        };

        combo_multiply {
            key-positions = <13 8 2>;
            bindings      = < &kp M &kp U &kp L >;
        };

        combo_nothing {
            key-positions = <9 7 11>;
            bindings      = < &kp N &kp O &kp H >;
        };

        combo_course {
            key-positions = <15 7 10>;
            bindings      = < &kp C &kp O &kp S >;
        };

        combo_stay {
            key-positions = <10 12 16 14>;
            bindings      = < &kp S &kp T &kp A &kp Y >;
        };

        combo_wheel {
            key-positions = <24 11 17 2>;
            bindings      = < &kp W &kp H &kp E &kp L >;
        };

        combo_full {
            key-positions = <1 8 2>;
            bindings      = < &kp F &kp U &kp L >;
        };

        combo_force {
            key-positions = <1 7 15>;
            bindings      = < &kp F &kp O &kp C >;
        };

        combo_blue {
            key-positions = <0 2 8 17>;
            bindings      = < &kp B &kp L &kp U &kp E >;
        };

        combo_object {
            key-positions = <7 0 21>;
            bindings      = < &kp O &kp B &kp J >;
        };

        combo_decide {
            key-positions = <22 17 15 18>;
            bindings      = < &kp D &kp E &kp C &kp I >;
        };

        combo_surface {
            key-positions = <10 8 25>;
            bindings      = < &kp S &kp U &kp R >;
        };

        combo_deep {
            key-positions = <22 17 5>;
            bindings      = < &kp D &kp E &kp P >;
        };

        combo_island {
            key-positions = <18 10 16>;
            bindings      = < &kp I &kp S &kp A >;
        };

        combo_system {
            key-positions = <10 14 12>;
            bindings      = < &kp S &kp Y &kp T >;
        };

        combo_busy {
            key-positions = <0 8 10 14>;
            bindings      = < &kp B &kp U &kp S &kp Y >;
        };

        combo_record {
            key-positions = <25 15 22>;
            bindings      = < &kp R &kp C &kp D >;
        };

        combo_boat {
            key-positions = <0 7 16 12>;
            bindings      = < &kp B &kp O &kp A &kp T >;
        };

        combo_common {
            key-positions = <15 7 13 9>;
            bindings      = < &kp C &kp O &kp M &kp N >;
        };

        combo_gold {
            key-positions = <6 7 2 22>;
            bindings      = < &kp G &kp O &kp L &kp D >;
        };

        combo_possible {
            key-positions = <5 7 10>;
            bindings      = < &kp P &kp O &kp S >;
        };

        combo_plane {
            key-positions = <5 2 17>;
            bindings      = < &kp P &kp L &kp E >;
        };

        combo_stead {
            key-positions = <10 12 22>;
            bindings      = < &kp S &kp T &kp D >;
        };

        combo_dry {
            key-positions = <22 25 14>;
            bindings      = < &kp D &kp R &kp Y >;
        };

        combo_wonder {
            key-positions = <24 9 22>;
            bindings      = < &kp W &kp N &kp D >;
        };

        combo_laugh {
            key-positions = <2 16 8>;
            bindings      = < &kp L &kp A &kp U >;
        };

        combo_thousand {
            key-positions = <12 11 22>;
            bindings      = < &kp T &kp H &kp D >;
        };

        combo_ago {
            key-positions = <16 6 7>;
            bindings      = < &kp A &kp G &kp O >;
        };

        combo_ran {
            key-positions = <25 16 9>;
            bindings      = < &kp R &kp A &kp N >;
        };

        combo_check {
            key-positions = <15 11 17 3>;
            bindings      = < &kp C &kp H &kp E &kp K >;
        };

        combo_game {
            key-positions = <6 16 13 17>;
            bindings      = < &kp G &kp A &kp M &kp E >;
        };

        combo_shape {
            key-positions = <10 11 5>;
            bindings      = < &kp S &kp H &kp P >;
        };

        combo_equate {
            key-positions = <17 4 8>;
            bindings      = < &kp E &kp Q &kp U >;
        };

        combo_brought {
            key-positions = <0 25 7>;
            bindings      = < &kp B &kp R &kp O >;
        };

        combo_heat {
            key-positions = <11 17 16 12>;
            bindings      = < &kp H &kp E &kp A &kp T >;
        };

        combo_snow {
            key-positions = <10 9 7 24>;
            bindings      = < &kp S &kp N &kp O &kp W >;
        };

        combo_tire {
            key-positions = <12 18 25 17>;
            bindings      = < &kp T &kp I &kp R &kp E >;
        };

        combo_bring {
            key-positions = <0 25 18>;
            bindings      = < &kp B &kp R &kp I >;
        };

        combo_yes {
            key-positions = <14 17 10>;
            bindings      = < &kp Y &kp E &kp S >;
        };

        combo_distant {
            key-positions = <22 18 10>;
            bindings      = < &kp D &kp I &kp S >;
        };

        combo_fill {
            key-positions = <1 18 2>;
            bindings      = < &kp F &kp I &kp L >;
        };

        combo_paint {
            key-positions = <5 16 18>;
            bindings      = < &kp P &kp A &kp I >;
        };

        combo_language {
            key-positions = <2 16 9>;
            bindings      = < &kp L &kp A &kp N >;
        };

        combo_among {
            key-positions = <16 13 7>;
            bindings      = < &kp A &kp M &kp O >;
        };

        combo_grand {
            key-positions = <6 25 16>;
            bindings      = < &kp G &kp R &kp A >;
        };

        combo_yet {
            key-positions = <14 17 12>;
            bindings      = < &kp Y &kp E &kp T >;
        };

        combo_wave {
            key-positions = <24 16 20 17>;
            bindings      = < &kp W &kp A &kp V &kp E >;
        };

        combo_drop {
            key-positions = <22 25 7 5>;
            bindings      = < &kp D &kp R &kp O &kp P >;
        };

        combo_heart {
            key-positions = <11 16 25>;
            bindings      = < &kp H &kp A &kp R >;
        };

        combo_am {
            key-positions = <16 13>;
            bindings      = < &kp A &kp M >;
        };

        combo_present {
            key-positions = <5 25 10>;
            bindings      = < &kp P &kp R &kp S >;
        };

        combo_heavy {
            key-positions = <11 17 20>;
            bindings      = < &kp H &kp E &kp V >;
        };

        combo_dance {
            key-positions = <22 16 15>;
            bindings      = < &kp D &kp A &kp C >;
        };

        combo_engine {
            key-positions = <17 9 6 18>;
            bindings      = < &kp E &kp N &kp G &kp I >;
        };

        combo_position {
            key-positions = <5 7 9>;
            bindings      = < &kp P &kp O &kp N >;
        };

        combo_arm {
            key-positions = <16 25 13>;
            bindings      = < &kp A &kp R &kp M >;
        };

        combo_wide {
            key-positions = <24 18 22 17>;
            bindings      = < &kp W &kp I &kp D &kp E >;
        };

        combo_sail {
            key-positions = <10 16 18 2>;
            bindings      = < &kp S &kp A &kp I &kp L >;
        };

        combo_material {
            key-positions = <13 16 12>;
            bindings      = < &kp M &kp A &kp T >;
        };

        combo_size {
            key-positions = <10 18 23 17>;
            bindings      = < &kp S &kp I &kp Z &kp E >;
        };

        combo_vary {
            key-positions = <20 16 25 14>;
            bindings      = < &kp V &kp A &kp R &kp Y >;
        };

        combo_settle {
            key-positions = <10 17 12 2>;
            bindings      = < &kp S &kp E &kp T &kp L >;
        };

        combo_speak {
            key-positions = <10 5 3>;
            bindings      = < &kp S &kp P &kp K >;
        };

        combo_weight {
            key-positions = <24 17 18>;
            bindings      = < &kp W &kp E &kp I >;
        };

        combo_general {
            key-positions = <6 17 9>;
            bindings      = < &kp G &kp E &kp N >;
        };

        combo_ice {
            key-positions = <18 15 17>;
            bindings      = < &kp I &kp C &kp E >;
        };

        combo_matter {
            key-positions = <13 12 25>;
            bindings      = < &kp M &kp T &kp R >;
        };

        combo_circle {
            key-positions = <15 18 25>;
            bindings      = < &kp C &kp I &kp R >;
        };

        combo_pair {
            key-positions = <5 16 18 25>;
            bindings      = < &kp P &kp A &kp I &kp R >;
        };

        combo_include {
            key-positions = <18 9 15>;
            bindings      = < &kp I &kp N &kp C >;
        };

        combo_divide {
            key-positions = <22 18 20 17>;
            bindings      = < &kp D &kp I &kp V &kp E >;
        };

        combo_syllable {
            key-positions = <10 14 2>;
            bindings      = < &kp S &kp Y &kp L >;
        };

        combo_perhaps {
            key-positions = <5 17 11>;
            bindings      = < &kp P &kp E &kp H >;
        };

        combo_pick {
            key-positions = <5 18 15 3>;
            bindings      = < &kp P &kp I &kp C &kp K >;
        };

        combo_sudden {
            key-positions = <10 8 22>;
            bindings      = < &kp S &kp U &kp D >;
        };

        combo_count {
            key-positions = <15 8 9>;
            bindings      = < &kp C &kp U &kp N >;
        };

        combo_square {
            key-positions = <10 4 8>;
            bindings      = < &kp S &kp Q &kp U >;
        };

        combo_reason {
            key-positions = <25 10 9>;
            bindings      = < &kp R &kp S &kp N >;
        };

        combo_length {
            key-positions = <2 17 9>;
            bindings      = < &kp L &kp E &kp N >;
        };

        combo_subject {
            key-positions = <10 8 0>;
            bindings      = < &kp S &kp U &kp B >;
        };

        combo_region {
            key-positions = <25 17 18>;
            bindings      = < &kp R &kp E &kp I >;
        };

        combo_energy {
            key-positions = <17 9 25>;
            bindings      = < &kp E &kp N &kp R >;
        };

        combo_hunt {
            key-positions = <11 8 9 12>;
            bindings      = < &kp H &kp U &kp N &kp T >;
        };

        combo_probable {
            key-positions = <5 7 0>;
            bindings      = < &kp P &kp O &kp B >;
        };

        combo_bed {
            key-positions = <0 17 22>;
            bindings      = < &kp B &kp E &kp D >;
        };

        combo_brother {
            key-positions = <0 25 12>;
            bindings      = < &kp B &kp R &kp T >;
        };

        combo_egg {
            key-positions = <17 6>;
            bindings      = < &kp E &kp G >;
        };

        combo_ride {
            key-positions = <25 18 22 17>;
            bindings      = < &kp R &kp I &kp D &kp E >;
        };

    };
};
